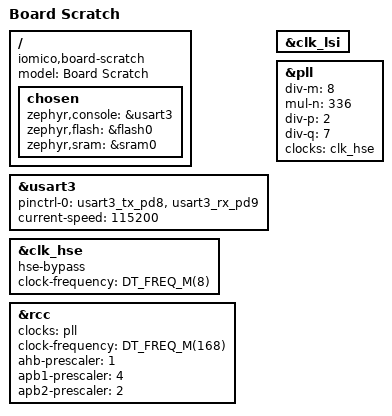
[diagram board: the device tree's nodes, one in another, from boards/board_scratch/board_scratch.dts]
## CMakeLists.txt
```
cmake_minimum_required(VERSION 3.20.0)

list(APPEND BOARD_ROOT ${CMAKE_CURRENT_SOURCE_DIR})
list(APPEND ZEPHYR_EXTRA_MODULES ${CMAKE_CURRENT_SOURCE_DIR}/modules/our_custom_drivers)
find_package(Zephyr REQUIRED)
project(my_zephyr_app)

target_sources(app PRIVATE src/main.c src/sensor_shell.c)
```

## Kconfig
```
source "Kconfig.zephyr"

# Module 4 task ------------------------------------------------------------
config APP_HEARTBEAT_PERIOD_MS
    int "Heartbeat period (100-2000 ms)"
    range 100 2000
    default 500


# Module 3 task (unused) ----------------------------------------------------
menuconfig LED_SUBSYSTEM
    bool "LED Subsystem"
    default y
    
if LED_SUBSYSTEM

    choice LED_BLINK_SLEEP_TIME_CHOICE
        prompt "LED blink sleep time"
        default LED_BLINK_SLEEP_MEDIUM

        config LED_BLINK_SLEEP_SHORT
            bool "100ms (short)"
        config LED_BLINK_SLEEP_MEDIUM
            bool "1s (medium)"
        config LED_BLINK_SLEEP_LONG
            bool "5s (long)"
    endchoice

    menuconfig LED_ADVANCED_SETTINGS
        bool "Advanced LED settings"
        default n
   
    if LED_ADVANCED_SETTINGS
        config LED_BRIGHTNESS
            int "LED brightness (0-100)"
            range 0 100
            default 100

        config LED_FADE_DURATION
            int "LED fade duration (ms)"
            default 500

        menu "Expert settings"
            config LED_DEBUGGING
                bool "Enable LED debugging"
                default n

            config LED_CUSTOM_BLINK_PATTERN
                bool "Custom blink pattern"
                default n
        endmenu
    endif
endif
```

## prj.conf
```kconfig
CONFIG_GPIO=y
CONFIG_LOG=y
CONFIG_SENSOR=y
CONFIG_SHELL=y
CONFIG_SENSOR_SHELL=n
```

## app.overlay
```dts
/ {
    aliases {
        app-led = &green_led_1; // The user LED for my board: b_l4s5i_iot01a
    };

    our_led_sensor: our_led_sensor {
        compatible = "our,driver";
        led-gpios = <&gpioa 5 GPIO_ACTIVE_HIGH>;
    };
};
```

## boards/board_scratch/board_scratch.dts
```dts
/dts-v1/;
#include<st/f4/stm32f429Xi.dtsi>
#include<st/f4/stm32f429zitx-pinctrl.dtsi>
#include<zephyr/dt-bindings/input/input-event-codes.h>

/{
    model="Board Scratch";
    compatible="iomico,board-scratch";
    chosen{
        zephyr,console = &usart3;
        zephyr,flash=&flash0;
        zephyr,sram=&sram0;/* Point to regular RAM */
    };
};

&usart3 {
        pinctrl-0 = <&usart3_tx_pd8 &usart3_rx_pd9>;
        pinctrl-names = "default";
        current-speed = <115200>;
        status = "okay";
};

&clk_lsi {
	status = "okay";
};

&clk_hse {
	hse-bypass;
	clock-frequency = <DT_FREQ_M(8)>; /* STLink 8MHz clock */
	status = "okay";
};

&pll {
	div-m = <8>;
	mul-n = <336>;
	div-p = <2>;
	div-q = <7>;
	clocks = <&clk_hse>;
	status = "okay";
};

&rcc {
	clocks = <&pll>;
	clock-frequency = <DT_FREQ_M(168)>; /* highest value to get a precise USB clock */
	ahb-prescaler = <1>;
	apb1-prescaler = <4>;
	apb2-prescaler = <2>;
};
```

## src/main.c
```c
#include "zephyr/drivers/sensor.h"
#include <zephyr/kernel.h>
#include <zephyr/device.h>
#include <zephyr/drivers/gpio.h>
#include <zephyr/logging/log.h>
#include <our_driver/our_driver.h>

/* The devicetree node identifier for the "led0" alias. */
#define LED_NODE DT_ALIAS(app_led)

static const struct device *const led_dev = DEVICE_DT_GET(DT_NODELABEL(our_led_sensor));

LOG_MODULE_REGISTER(main, LOG_LEVEL_INF);

int main(void) {
    struct sensor_value val;
    int count = 0;

    if (!device_is_ready(led_dev)) {
        LOG_ERR("our_driver not ready");
        return 0;
    }

    while (1) {
        sensor_sample_fetch(led_dev);                        /* LED on (if enabled) */
        k_msleep(CONFIG_APP_HEARTBEAT_PERIOD_MS);
        sensor_channel_get(led_dev, SENSOR_CHAN_ALL, &val);  /* LED off */
        k_msleep(CONFIG_APP_HEARTBEAT_PERIOD_MS);

        count++;
        if (count % 5 == 0) {
            bool enable = (count / 5) % 2 == 0;
            our_driver_set_enabled(led_dev, enable);         /* extension API call */
            LOG_INF("LED %s", enable ? "enabled" : "disabled");
        }
    }
    return 0;
}
```

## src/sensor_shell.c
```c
#include <zephyr/kernel.h>
#include <zephyr/device.h>
#include <zephyr/drivers/sensor.h>
#include <zephyr/shell/shell.h>
#include <our_driver/our_driver.h>

static const struct device *const sensor_dev = DEVICE_DT_GET(DT_NODELABEL(our_led_sensor));

static int cmd_fetch(const struct shell *sh, size_t argc, char **argv) {
    if (!device_is_ready(sensor_dev)) {
        shell_error(sh, "%s not ready", sensor_dev->name);
        return -ENODEV;
    }

    int result = sensor_sample_fetch(sensor_dev);
    if (result < 0) {
        shell_error(sh, "sensor_sample_fetch failed: %d", result);
        return result;
    }

    shell_print(sh, "fetch OK");
    return 0;
}

static int cmd_read(const struct shell *sh, size_t argc, char **argv) {
    struct sensor_value val = {0};

    if (!device_is_ready(sensor_dev)) {
        shell_error(sh, "%s not ready", sensor_dev->name);
        return -ENODEV;
    }

    int value = sensor_channel_get(sensor_dev, SENSOR_CHAN_ALL, &val);
    if (value < 0) {
        shell_error(sh, "sensor_channel_get failed: %d", value);
        return value;
    }

    shell_print(sh, "value: %d.%06d", val.val1, val.val2);
    return 0;
}

static int cmd_info(const struct shell *sh, size_t argc, char **argv) {
    shell_print(sh, "name:  %s", sensor_dev->name);
    shell_print(sh, "ready: %s", device_is_ready(sensor_dev) ? "yes" : "no");
    return 0;
}

// l7-task2 command
static int cmd_set(const struct shell *sh, size_t argc, char **argv) {
    int error = 0;

    if (argc < 2) { // Extra check on top of SHELL_CMD_ARG
        shell_error(sh, "missing argument: sensor set <0|1>");
        return -EINVAL;
    }

    unsigned long value = shell_strtoul(argv[1], 10, &error);
    if (error != 0) {
        shell_error(sh, "invalid number: '%s'", argv[1]);
        return -EINVAL;
    }
    if (value > 1) { // Can only set true or false for my custom command
        shell_error(sh, "out of range: %lu (expected 0 or 1)", value);
        return -ERANGE;
    }

    if (!device_is_ready(sensor_dev)) {
        shell_error(sh, "%s not ready", sensor_dev->name);
        return -ENODEV;
    }

    int result = our_driver_set_enabled(sensor_dev, value == 1);
    if (result < 0) {
        shell_error(sh, "our_driver_set_enabled failed: %d", result);
        return result;
    }

    shell_print(sh, "LED %s", value ? "enabled" : "disabled");
    return 0;
}

// The sensor subcommands table
SHELL_STATIC_SUBCMD_SET_CREATE(sub_sensor,
    SHELL_CMD(fetch, NULL, "Fetch a sample (sensor_sample_fetch)", cmd_fetch),
    SHELL_CMD(read,  NULL, "Read channel value (sensor_channel_get)", cmd_read),
    SHELL_CMD(info,  NULL, "Show device name and ready state", cmd_info),

    SHELL_CMD_ARG(set, NULL, "Enable/disable the LED: set <0|1>", cmd_set, 2, 0), // mandatory = 2 ("set" + value), optional = 0
    SHELL_SUBCMD_SET_END
);

// Root command with no handler, points to subcommand table
SHELL_CMD_REGISTER(sensor, &sub_sensor, "Our LED sensor commands", NULL);
```
